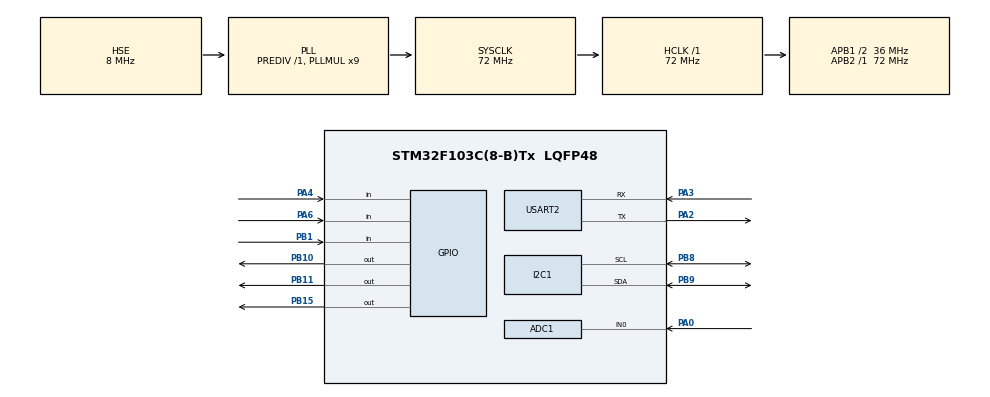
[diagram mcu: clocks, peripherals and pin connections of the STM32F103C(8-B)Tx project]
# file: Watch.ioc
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ADC1.Channel-0\#ChannelRegularConversion=ADC_CHANNEL_0
ADC1.NbrOfConversionFlag=1
ADC1.Rank-0\#ChannelRegularConversion=1
ADC1.SamplingTime-0\#ChannelRegularConversion=ADC_SAMPLETIME_1CYCLE_5
ADC1.master=1
I2C1.I2C_Mode=I2C_Fast
Mcu.Family=STM32F1
Mcu.Name=STM32F103C(8-B)Tx
Mcu.Package=LQFP48
NVIC.PriorityGroup=NVIC_PRIORITYGROUP_4
NVIC.TIM2_IRQn=true\:0\:0\:false\:false\:true\:true\:true\:true
NVIC.USART2_IRQn=true\:0\:0\:false\:false\:true\:true\:true\:true
PA0-WKUP.Signal=ADCx_IN0
PA13.Mode=Serial_Wire
PA13.Signal=SYS_JTMS-SWDIO
PA14.Mode=Serial_Wire
PA14.Signal=SYS_JTCK-SWCLK
PA2.Mode=Asynchronous
PA2.Signal=USART2_TX
PA3.Mode=Asynchronous
PA3.Signal=USART2_RX
PA4.GPIO_PuPd=GPIO_PULLUP
PA4.Signal=GPIO_Input
PA6.GPIO_PuPd=GPIO_PULLUP
PA6.Signal=GPIO_Input
PB1.GPIO_PuPd=GPIO_PULLUP
PB1.Signal=GPIO_Input
PB10.GPIO_ModeDefaultOutputPP=GPIO_MODE_OUTPUT_OD
PB10.GPIO_PuPd=GPIO_PULLUP
PB10.GPIO_Speed=GPIO_SPEED_FREQ_HIGH
PB10.PinState=GPIO_PIN_SET
PB10.Signal=GPIO_Output
PB11.GPIO_ModeDefaultOutputPP=GPIO_MODE_OUTPUT_OD
PB11.GPIO_PuPd=GPIO_PULLUP
PB11.GPIO_Speed=GPIO_SPEED_FREQ_HIGH
PB11.PinState=GPIO_PIN_SET
PB11.Signal=GPIO_Output
PB15.GPIO_Speed=GPIO_SPEED_FREQ_HIGH
PB15.PinState=GPIO_PIN_SET
PB15.Signal=GPIO_Output
PB8.Mode=I2C
PB8.Signal=I2C1_SCL
PB9.Mode=I2C
PB9.Signal=I2C1_SDA
PC14-OSC32_IN.Mode=LSE-External-Oscillator
PC14-OSC32_IN.Signal=RCC_OSC32_IN
PC15-OSC32_OUT.Mode=LSE-External-Oscillator
PC15-OSC32_OUT.Signal=RCC_OSC32_OUT
PD0-OSC_IN.Mode=HSE-External-Oscillator
PD0-OSC_IN.Signal=RCC_OSC_IN
PD1-OSC_OUT.Mode=HSE-External-Oscillator
PD1-OSC_OUT.Signal=RCC_OSC_OUT
ProjectManager.HeapSize=0x200
ProjectManager.StackSize=0x400
ProjectManager.TargetToolchain=MDK-ARM V5.32
RCC.ADCPresc=RCC_ADCPCLK2_DIV6
RCC.AHBFreq_Value=72000000
RCC.APB1CLKDivider=RCC_HCLK_DIV2
RCC.APB1Freq_Value=36000000
RCC.APB1TimFreq_Value=72000000
RCC.APB2Freq_Value=72000000
RCC.APB2TimFreq_Value=72000000
RCC.HCLKFreq_Value=72000000
RCC.PLLMUL=RCC_PLL_MUL9
RCC.PLLSourceVirtual=RCC_PLLSOURCE_HSE
RCC.RTCClockSelection=RCC_RTCCLKSOURCE_LSE
RCC.SYSCLKFreq_VALUE=72000000
RCC.SYSCLKSource=RCC_SYSCLKSOURCE_PLLCLK
RCC.USBFreq_Value=72000000
SH.ADCx_IN0.0=ADC1_IN0,IN0
USART2.VirtualMode=VM_ASYNC
VP_RTC_VS_RTC_Activate.Mode=RTC_Enabled
VP_TIM2_VS_ClockSourceINT.Mode=Internal
board=custom

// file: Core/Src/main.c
/* USER CODE BEGIN Header */
/**
  ******************************************************************************
  * @file           : main.c
  * @brief          : Main program body
  ******************************************************************************
  * @attention
  *
  * Copyright (c) 2026 STMicroelectronics.
  * All rights reserved.
  *
  * This software is licensed under terms that can be found in the LICENSE file
  * in the root directory of this software component.
  * If no LICENSE file comes with this software, it is provided AS-IS.
  *
  ******************************************************************************
  */
/* USER CODE END Header */
#include "main.h"
#include "adc.h"
#include "i2c.h"
#include "rtc.h"
#include "tim.h"
#include "usart.h"
#include "gpio.h"

/* USER CODE BEGIN Includes */
#include "Freertos_Task.h"
/* USER CODE END Includes */

void SystemClock_Config(void);

int main(void)
{

  /* MCU Configuration--------------------------------------------------------*/

  /* Reset of all peripherals, Initializes the Flash interface and the Systick. */
  HAL_Init();

  /* Configure the system clock */
  SystemClock_Config();

  /* Initialize all configured peripherals */
  MX_GPIO_Init();
  MX_USART2_UART_Init();
  MX_I2C1_Init();
  MX_TIM2_Init();
  MX_ADC1_Init();
  MX_RTC_Init();
  /* USER CODE BEGIN 2 */

//  Debug_Printf("Hello World\n");

  //启动FReeRTOS
  FreeRTOS_Start();

  /* USER CODE END 2 */

  /* Infinite loop */
  while (1)
  {

  }
}

void SystemClock_Config(void)
{
  RCC_OscInitTypeDef RCC_OscInitStruct = {0};
  RCC_ClkInitTypeDef RCC_ClkInitStruct = {0};
  RCC_PeriphCLKInitTypeDef PeriphClkInit = {0};

  /** Initializes the RCC Oscillators according to the specified parameters
  * in the RCC_OscInitTypeDef structure.
  */
  RCC_OscInitStruct.OscillatorType = RCC_OSCILLATORTYPE_HSE|RCC_OSCILLATORTYPE_LSE;
  RCC_OscInitStruct.HSEState = RCC_HSE_ON;
  RCC_OscInitStruct.HSEPredivValue = RCC_HSE_PREDIV_DIV1;
  RCC_OscInitStruct.LSEState = RCC_LSE_ON;
  RCC_OscInitStruct.HSIState = RCC_HSI_ON;
  RCC_OscInitStruct.PLL.PLLState = RCC_PLL_ON;
  RCC_OscInitStruct.PLL.PLLSource = RCC_PLLSOURCE_HSE;
  RCC_OscInitStruct.PLL.PLLMUL = RCC_PLL_MUL9;
  if (HAL_RCC_OscConfig(&RCC_OscInitStruct) != HAL_OK)
  {
    Error_Handler();
  }

  /** Initializes the CPU, AHB and APB buses clocks
  */
  RCC_ClkInitStruct.ClockType = RCC_CLOCKTYPE_HCLK|RCC_CLOCKTYPE_SYSCLK
                              |RCC_CLOCKTYPE_PCLK1|RCC_CLOCKTYPE_PCLK2;
  RCC_ClkInitStruct.SYSCLKSource = RCC_SYSCLKSOURCE_PLLCLK;
  RCC_ClkInitStruct.AHBCLKDivider = RCC_SYSCLK_DIV1;
  RCC_ClkInitStruct.APB1CLKDivider = RCC_HCLK_DIV2;
  RCC_ClkInitStruct.APB2CLKDivider = RCC_HCLK_DIV1;

  if (HAL_RCC_ClockConfig(&RCC_ClkInitStruct, FLASH_LATENCY_2) != HAL_OK)
  {
    Error_Handler();
  }
  PeriphClkInit.PeriphClockSelection = RCC_PERIPHCLK_RTC|RCC_PERIPHCLK_ADC;
  PeriphClkInit.RTCClockSelection = RCC_RTCCLKSOURCE_LSE;
  PeriphClkInit.AdcClockSelection = RCC_ADCPCLK2_DIV6;
  if (HAL_RCCEx_PeriphCLKConfig(&PeriphClkInit) != HAL_OK)
  {
    Error_Handler();
  }
}

void Error_Handler(void)
{
  __disable_irq();
  while (1)
  {
  }
}
